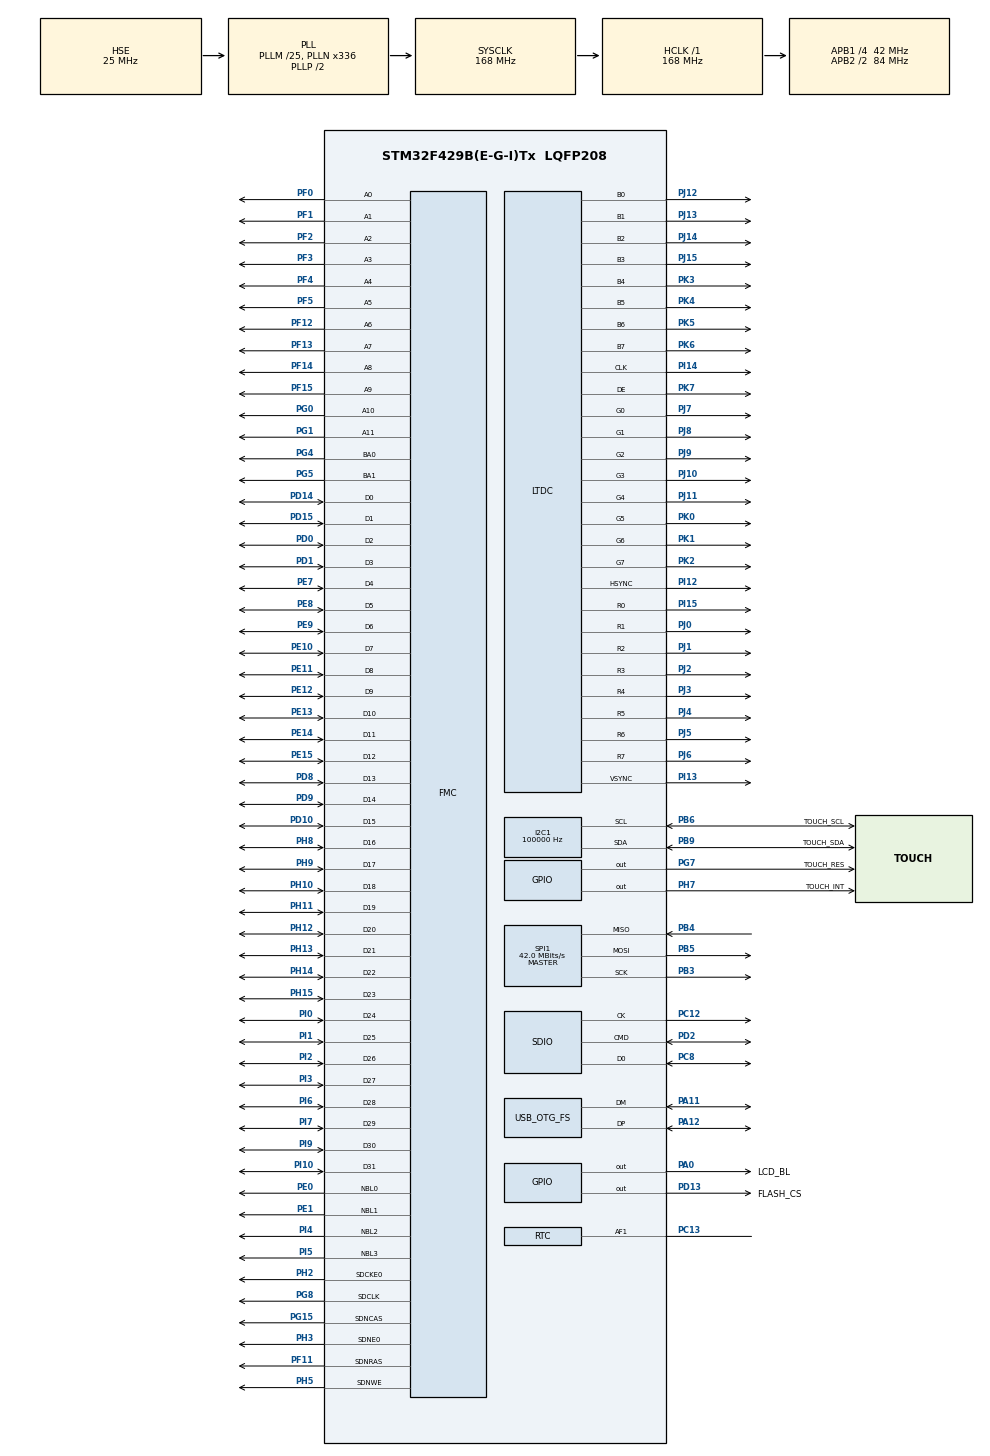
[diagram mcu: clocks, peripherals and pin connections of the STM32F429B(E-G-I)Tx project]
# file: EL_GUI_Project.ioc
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DMA2D.ColorMode=DMA2D_OUTPUT_RGB565
Dma.Request0=SPI1_RX
Dma.Request1=SPI1_TX
Dma.SPI1_RX.0.Direction=DMA_PERIPH_TO_MEMORY
Dma.SPI1_RX.0.FIFOMode=DMA_FIFOMODE_DISABLE
Dma.SPI1_RX.0.Instance=DMA2_Stream0
Dma.SPI1_RX.0.MemDataAlignment=DMA_MDATAALIGN_BYTE
Dma.SPI1_RX.0.MemInc=DMA_MINC_ENABLE
Dma.SPI1_RX.0.Mode=DMA_NORMAL
Dma.SPI1_RX.0.PeriphDataAlignment=DMA_PDATAALIGN_BYTE
Dma.SPI1_RX.0.PeriphInc=DMA_PINC_DISABLE
Dma.SPI1_RX.0.Priority=DMA_PRIORITY_LOW
Dma.SPI1_TX.1.Direction=DMA_MEMORY_TO_PERIPH
Dma.SPI1_TX.1.FIFOMode=DMA_FIFOMODE_DISABLE
Dma.SPI1_TX.1.Instance=DMA2_Stream3
Dma.SPI1_TX.1.MemDataAlignment=DMA_MDATAALIGN_BYTE
Dma.SPI1_TX.1.MemInc=DMA_MINC_DISABLE
Dma.SPI1_TX.1.Mode=DMA_NORMAL
Dma.SPI1_TX.1.PeriphDataAlignment=DMA_PDATAALIGN_BYTE
Dma.SPI1_TX.1.PeriphInc=DMA_PINC_DISABLE
Dma.SPI1_TX.1.Priority=DMA_PRIORITY_LOW
FMC.CASLatency1=FMC_SDRAM_CAS_LATENCY_3
FMC.ExitSelfRefreshDelay1=7
FMC.LoadToActiveDelay1=2
FMC.RCDDelay1=2
FMC.RPDelay1=2
FMC.ReadBurst1=FMC_SDRAM_RBURST_ENABLE
FMC.RowCycleDelay1=7
FMC.SDClockPeriod1=FMC_SDRAM_CLOCK_PERIOD_2
FMC.SelfRefreshTime1=4
FMC.WriteRecoveryTime1=3
FREERTOS.Tasks01=GUI_Task,24,8192,TouchGFX_Task_start,Default,NULL,Dynamic,NULL,NULL
FREERTOS.configENABLE_FPU=1
FREERTOS.configTOTAL_HEAP_SIZE=49152
FREERTOS.configUSE_NEWLIB_REENTRANT=1
I2C1.ClockSpeed=100000
LTDC.ActiveH=480
LTDC.ActiveW=800
LTDC.Alpha0_L0=0
LTDC.Alpha_L0=255
LTDC.Blue_L0=0
LTDC.DEPolarity=LTDC_DEPOLARITY_AL
LTDC.FBStartAdress_L0=0xC0000000
LTDC.FBStartAdress_L1=0xC0200000
LTDC.Green_L0=0
LTDC.HBP=46
LTDC.HFP=210
LTDC.HSPolarity=LTDC_HSPOLARITY_AH
LTDC.HSync=10
LTDC.ImageHeight_L0=480
LTDC.ImageHeight_L1=480
LTDC.ImageWidth_L0=800
LTDC.ImageWidth_L1=800
LTDC.Layers=0
LTDC.PCPolarity=LTDC_PCPOLARITY_IPC
LTDC.PixelFormat_L0=LTDC_PIXEL_FORMAT_RGB565
LTDC.Red_L0=0
LTDC.VBP=23
LTDC.VFP=22
LTDC.VSPolarity=LTDC_VSPOLARITY_AH
LTDC.VSync=10
LTDC.WindowX1_L0=800
LTDC.WindowX1_L1=800
LTDC.WindowY1_L0=480
LTDC.WindowY1_L1=480
Mcu.Family=STM32F4
Mcu.Name=STM32F429B(E-G-I)Tx
Mcu.Package=LQFP208
NVIC.DMA2_Stream0_IRQn=true\:5\:0\:false\:false\:true\:true\:true\:true\:true
NVIC.DMA2_Stream3_IRQn=true\:5\:0\:false\:false\:true\:true\:true\:true\:true
NVIC.FLASH_IRQn=true\:5\:0\:true\:false\:true\:true\:true\:true\:true
NVIC.FMC_IRQn=true\:5\:0\:true\:false\:true\:true\:true\:true\:true
NVIC.FPU_IRQn=true\:5\:0\:true\:false\:true\:true\:true\:false\:true
NVIC.LTDC_ER_IRQn=true\:5\:0\:true\:false\:true\:true\:true\:true\:true
NVIC.LTDC_IRQn=true\:5\:0\:true\:false\:true\:true\:true\:true\:true
NVIC.OTG_FS_IRQn=true\:5\:0\:false\:false\:true\:true\:false\:true\:true
NVIC.PriorityGroup=NVIC_PRIORITYGROUP_4
NVIC.RCC_IRQn=true\:5\:0\:true\:false\:true\:true\:true\:false\:true
NVIC.SDIO_IRQn=true\:5\:0\:false\:false\:true\:true\:true\:true\:true
NVIC.SPI1_IRQn=true\:5\:0\:false\:false\:true\:true\:true\:true\:true
NVIC.TIM8_TRG_COM_TIM14_IRQn=true\:4\:0\:true\:false\:true\:false\:false\:true\:true
NVIC.TimeBase=TIM8_TRG_COM_TIM14_IRQn
NVIC.TimeBaseIP=TIM14
PA0/WKUP.GPIO_Label=LCD_BL
PA0/WKUP.Signal=GPIO_Output
PA11.Mode=Device_Only
PA11.Signal=USB_OTG_FS_DM
PA12.Mode=Device_Only
PA12.Signal=USB_OTG_FS_DP
PA13.Mode=Serial_Wire
PA13.Signal=SYS_JTMS-SWDIO
PA14.Mode=Serial_Wire
PA14.Signal=SYS_JTCK-SWCLK
PB3.Mode=Full_Duplex_Master
PB3.Signal=SPI1_SCK
PB4.Mode=Full_Duplex_Master
PB4.Signal=SPI1_MISO
PB5.Mode=Full_Duplex_Master
PB5.Signal=SPI1_MOSI
PB6.GPIO_Label=TOUCH_SCL
PB6.GPIO_Pu=GPIO_NOPULL
PB6.GPIO_Speed=GPIO_SPEED_FREQ_VERY_HIGH
PB6.Mode=I2C
PB6.Signal=I2C1_SCL
PB9.GPIO_Label=TOUCH_SDA
PB9.GPIO_Pu=GPIO_NOPULL
PB9.Mode=I2C
PB9.Signal=I2C1_SDA
PC12.GPIO_PuPd=GPIO_PULLUP
PC12.Mode=SD_1_bit
PC12.Signal=SDIO_CK
PC13.Mode=Calibration_512Hz
PC13.Signal=RTC_AF1
PC14/OSC32_IN.Mode=LSE-External-Oscillator
PC14/OSC32_IN.Signal=RCC_OSC32_IN
PC15/OSC32_OUT.Mode=LSE-External-Oscillator
PC15/OSC32_OUT.Signal=RCC_OSC32_OUT
PC8.GPIO_PuPd=GPIO_PULLUP
PC8.Mode=SD_1_bit
PC8.Signal=SDIO_D0
PD0.Signal=FMC_D2_DA2
PD1.Signal=FMC_D3_DA3
PD10.Signal=FMC_D15_DA15
PD13.GPIO_Label=FLASH_CS
PD13.GPIO_Speed=GPIO_SPEED_FREQ_HIGH
PD13.PinState=GPIO_PIN_SET
PD13.Signal=GPIO_Output
PD14.Signal=FMC_D0_DA0
PD15.Signal=FMC_D1_DA1
PD2.GPIO_PuPd=GPIO_PULLUP
PD2.Mode=SD_1_bit
PD2.Signal=SDIO_CMD
PD8.Signal=FMC_D13_DA13
PD9.Signal=FMC_D14_DA14
PE0.Signal=FMC_NBL0
PE1.Signal=FMC_NBL1
PE10.Signal=FMC_D7_DA7
PE11.Signal=FMC_D8_DA8
PE12.Signal=FMC_D9_DA9
PE13.Signal=FMC_D10_DA10
PE14.Signal=FMC_D11_DA11
PE15.Signal=FMC_D12_DA12
PE7.Signal=FMC_D4_DA4
PE8.Signal=FMC_D5_DA5
PE9.Signal=FMC_D6_DA6
PF0.Signal=FMC_A0
PF1.Signal=FMC_A1
PF11.Signal=FMC_SDNRAS
PF12.Signal=FMC_A6
PF13.Signal=FMC_A7
PF14.Signal=FMC_A8
PF15.Signal=FMC_A9
PF2.Signal=FMC_A2
PF3.Signal=FMC_A3
PF4.Signal=FMC_A4
PF5.Signal=FMC_A5
PG0.Signal=FMC_A10
PG1.Signal=FMC_A11
PG15.Signal=FMC_SDNCAS
PG4.Signal=FMC_A14_BA0
PG5.Signal=FMC_A15_BA1
PG7.GPIO_Label=TOUCH_RES
PG7.PinState=GPIO_PIN_SET
PG7.Signal=GPIO_Output
PG8.Signal=FMC_SDCLK
PH0/OSC_IN.Mode=HSE-External-Oscillator
PH0/OSC_IN.Signal=RCC_OSC_IN
PH1/OSC_OUT.Mode=HSE-External-Oscillator
PH1/OSC_OUT.Signal=RCC_OSC_OUT
PH10.Signal=FMC_D18
PH11.Signal=FMC_D19
PH12.Signal=FMC_D20
PH13.Signal=FMC_D21
PH14.Signal=FMC_D22
PH15.Signal=FMC_D23
PH2.Mode=SdramChipSelect1_1
PH2.Signal=FMC_SDCKE0
PH3.Mode=SdramChipSelect1_1
PH3.Signal=FMC_SDNE0
PH5.Signal=FMC_SDNWE
PH7.GPIO_Label=TOUCH_INT
PH7.GPIO_Speed=GPIO_SPEED_FREQ_MEDIUM
PH7.PinState=GPIO_PIN_SET
PH7.Signal=GPIO_Output
PH8.Signal=FMC_D16
PH9.Signal=FMC_D17
PI0.Signal=FMC_D24
PI1.Signal=FMC_D25
PI10.Signal=FMC_D31
PI12.GPIO_PuPd=GPIO_NOPULL
PI12.GPIO_Speed=GPIO_SPEED_FREQ_VERY_HIGH
PI12.Mode=RGB888
PI12.Signal=LTDC_HSYNC
PI13.GPIO_PuPd=GPIO_NOPULL
PI13.GPIO_Speed=GPIO_SPEED_FREQ_VERY_HIGH
PI13.Mode=RGB888
PI13.Signal=LTDC_VSYNC
PI14.GPIO_PuPd=GPIO_NOPULL
PI14.GPIO_Speed=GPIO_SPEED_FREQ_VERY_HIGH
PI14.Mode=RGB888
PI14.Signal=LTDC_CLK
PI15.GPIO_PuPd=GPIO_NOPULL
PI15.GPIO_Speed=GPIO_SPEED_FREQ_VERY_HIGH
PI15.Mode=RGB888
PI15.Signal=LTDC_R0
PI2.Signal=FMC_D26
PI3.Signal=FMC_D27
PI4.Signal=FMC_NBL2
PI5.Signal=FMC_NBL3
PI6.Signal=FMC_D28
PI7.Signal=FMC_D29
PI9.Signal=FMC_D30
PJ0.GPIO_PuPd=GPIO_NOPULL
PJ0.GPIO_Speed=GPIO_SPEED_FREQ_VERY_HIGH
PJ0.Mode=RGB888
PJ0.Signal=LTDC_R1
PJ1.GPIO_PuPd=GPIO_NOPULL
PJ1.GPIO_Speed=GPIO_SPEED_FREQ_VERY_HIGH
PJ1.Mode=RGB888
PJ1.Signal=LTDC_R2
PJ10.GPIO_PuPd=GPIO_NOPULL
PJ10.GPIO_Speed=GPIO_SPEED_FREQ_VERY_HIGH
PJ10.Mode=RGB888
PJ10.Signal=LTDC_G3
PJ11.GPIO_PuPd=GPIO_NOPULL
PJ11.GPIO_Speed=GPIO_SPEED_FREQ_VERY_HIGH
PJ11.Mode=RGB888
PJ11.Signal=LTDC_G4
PJ12.GPIO_PuPd=GPIO_NOPULL
PJ12.GPIO_Speed=GPIO_SPEED_FREQ_VERY_HIGH
PJ12.Mode=RGB888
PJ12.Signal=LTDC_B0
PJ13.GPIO_PuPd=GPIO_NOPULL
PJ13.GPIO_Speed=GPIO_SPEED_FREQ_VERY_HIGH
PJ13.Mode=RGB888
PJ13.Signal=LTDC_B1
PJ14.GPIO_PuPd=GPIO_NOPULL
PJ14.GPIO_Speed=GPIO_SPEED_FREQ_VERY_HIGH
PJ14.Mode=RGB888
PJ14.Signal=LTDC_B2
PJ15.GPIO_PuPd=GPIO_NOPULL
PJ15.GPIO_Speed=GPIO_SPEED_FREQ_VERY_HIGH
PJ15.Mode=RGB888
PJ15.Signal=LTDC_B3
PJ2.GPIO_PuPd=GPIO_NOPULL
PJ2.GPIO_Speed=GPIO_SPEED_FREQ_VERY_HIGH
PJ2.Mode=RGB888
PJ2.Signal=LTDC_R3
PJ3.GPIO_PuPd=GPIO_NOPULL
PJ3.GPIO_Speed=GPIO_SPEED_FREQ_VERY_HIGH
PJ3.Mode=RGB888
PJ3.Signal=LTDC_R4
PJ4.GPIO_PuPd=GPIO_NOPULL
PJ4.GPIO_Speed=GPIO_SPEED_FREQ_VERY_HIGH
PJ4.Mode=RGB888
PJ4.Signal=LTDC_R5
PJ5.GPIO_PuPd=GPIO_NOPULL
PJ5.GPIO_Speed=GPIO_SPEED_FREQ_VERY_HIGH
PJ5.Mode=RGB888
PJ5.Signal=LTDC_R6
PJ6.GPIO_PuPd=GPIO_NOPULL
PJ6.GPIO_Speed=GPIO_SPEED_FREQ_VERY_HIGH
PJ6.Mode=RGB888
PJ6.Signal=LTDC_R7
PJ7.GPIO_PuPd=GPIO_NOPULL
PJ7.GPIO_Speed=GPIO_SPEED_FREQ_VERY_HIGH
PJ7.Mode=RGB888
PJ7.Signal=LTDC_G0
PJ8.GPIO_PuPd=GPIO_NOPULL
PJ8.GPIO_Speed=GPIO_SPEED_FREQ_VERY_HIGH
PJ8.Mode=RGB888
PJ8.Signal=LTDC_G1
PJ9.GPIO_PuPd=GPIO_NOPULL
PJ9.GPIO_Speed=GPIO_SPEED_FREQ_VERY_HIGH
PJ9.Mode=RGB888
PJ9.Signal=LTDC_G2
PK0.GPIO_PuPd=GPIO_NOPULL
PK0.GPIO_Speed=GPIO_SPEED_FREQ_VERY_HIGH
PK0.Mode=RGB888
PK0.Signal=LTDC_G5
PK1.GPIO_PuPd=GPIO_NOPULL
PK1.GPIO_Speed=GPIO_SPEED_FREQ_VERY_HIGH
PK1.Mode=RGB888
PK1.Signal=LTDC_G6
PK2.GPIO_PuPd=GPIO_NOPULL
PK2.GPIO_Speed=GPIO_SPEED_FREQ_VERY_HIGH
PK2.Mode=RGB888
PK2.Signal=LTDC_G7
PK3.GPIO_PuPd=GPIO_NOPULL
PK3.GPIO_Speed=GPIO_SPEED_FREQ_VERY_HIGH
PK3.Mode=RGB888
PK3.Signal=LTDC_B4
PK4.GPIO_PuPd=GPIO_NOPULL
PK4.GPIO_Speed=GPIO_SPEED_FREQ_VERY_HIGH
PK4.Mode=RGB888
PK4.Signal=LTDC_B5
PK5.GPIO_PuPd=GPIO_NOPULL
PK5.GPIO_Speed=GPIO_SPEED_FREQ_VERY_HIGH
PK5.Mode=RGB888
PK5.Signal=LTDC_B6
PK6.GPIO_PuPd=GPIO_NOPULL
PK6.GPIO_Speed=GPIO_SPEED_FREQ_VERY_HIGH
PK6.Mode=RGB888
PK6.Signal=LTDC_B7
PK7.GPIO_PuPd=GPIO_NOPULL
PK7.GPIO_Speed=GPIO_SPEED_FREQ_VERY_HIGH
PK7.Mode=RGB888
PK7.Signal=LTDC_DE
ProjectManager.HeapSize=0x800
ProjectManager.StackSize=0x1000
ProjectManager.TargetToolchain=STM32CubeIDE
RCC.48MHZClocksFreq_Value=48000000
RCC.AHBFreq_Value=168000000
RCC.APB1CLKDivider=RCC_HCLK_DIV4
RCC.APB1Freq_Value=42000000
RCC.APB1TimFreq_Value=84000000
RCC.APB2CLKDivider=RCC_HCLK_DIV2
RCC.APB2Freq_Value=84000000
RCC.APB2TimFreq_Value=168000000
RCC.CortexFreq_Value=168000000
RCC.DATA_CACHE_ENABLE=1
RCC.HCLKFreq_Value=168000000
RCC.HSE_VALUE=25000000
RCC.HSI_VALUE=16000000
RCC.INSTRUCTION_CACHE_ENABLE=1
RCC.PLLM=25
RCC.PLLN=336
RCC.PLLQ=7
RCC.PLLSAIN=136
RCC.PREFETCH_ENABLE=1
RCC.RCC_RTC_Clock_Source=RCC_RTCCLKSOURCE_LSE
RCC.RCC_RTC_Clock_SourceVirtual=RCC_RTCCLKSOURCE_LSE
RCC.SYSCLKFreq_VALUE=168000000
RCC.SYSCLKSource=RCC_SYSCLKSOURCE_PLLCLK
RCC.VCOOutputFreq_Value=336000000
SDIO.ClockDiv=8
SH.FMC_A0.0=FMC_A0,12b-sda1
SH.FMC_A1.0=FMC_A1,12b-sda1
SH.FMC_A10.0=FMC_A10,12b-sda1
SH.FMC_A11.0=FMC_A11,12b-sda1
SH.FMC_A14_BA0.0=FMC_BA0,FourSdramBanks1
SH.FMC_A15_BA1.0=FMC_BA1,FourSdramBanks1
SH.FMC_A2.0=FMC_A2,12b-sda1
SH.FMC_A3.0=FMC_A3,12b-sda1
SH.FMC_A4.0=FMC_A4,12b-sda1
SH.FMC_A5.0=FMC_A5,12b-sda1
SH.FMC_A6.0=FMC_A6,12b-sda1
SH.FMC_A7.0=FMC_A7,12b-sda1
SH.FMC_A8.0=FMC_A8,12b-sda1
SH.FMC_A9.0=FMC_A9,12b-sda1
SH.FMC_D0_DA0.0=FMC_D0,sd-32b-d1
SH.FMC_D10_DA10.0=FMC_D10,sd-32b-d1
SH.FMC_D11_DA11.0=FMC_D11,sd-32b-d1
SH.FMC_D12_DA12.0=FMC_D12,sd-32b-d1
SH.FMC_D13_DA13.0=FMC_D13,sd-32b-d1
SH.FMC_D14_DA14.0=FMC_D14,sd-32b-d1
SH.FMC_D15_DA15.0=FMC_D15,sd-32b-d1
SH.FMC_D16.0=FMC_D16,sd-32b-d1
SH.FMC_D17.0=FMC_D17,sd-32b-d1
SH.FMC_D18.0=FMC_D18,sd-32b-d1
SH.FMC_D19.0=FMC_D19,sd-32b-d1
SH.FMC_D1_DA1.0=FMC_D1,sd-32b-d1
SH.FMC_D20.0=FMC_D20,sd-32b-d1
SH.FMC_D21.0=FMC_D21,sd-32b-d1
SH.FMC_D22.0=FMC_D22,sd-32b-d1
SH.FMC_D23.0=FMC_D23,sd-32b-d1
SH.FMC_D24.0=FMC_D24,sd-32b-d1
SH.FMC_D25.0=FMC_D25,sd-32b-d1
SH.FMC_D26.0=FMC_D26,sd-32b-d1
SH.FMC_D27.0=FMC_D27,sd-32b-d1
SH.FMC_D28.0=FMC_D28,sd-32b-d1
SH.FMC_D29.0=FMC_D29,sd-32b-d1
SH.FMC_D2_DA2.0=FMC_D2,sd-32b-d1
SH.FMC_D30.0=FMC_D30,sd-32b-d1
SH.FMC_D31.0=FMC_D31,sd-32b-d1
SH.FMC_D3_DA3.0=FMC_D3,sd-32b-d1
SH.FMC_D4_DA4.0=FMC_D4,sd-32b-d1
SH.FMC_D5_DA5.0=FMC_D5,sd-32b-d1
SH.FMC_D6_DA6.0=FMC_D6,sd-32b-d1
SH.FMC_D7_DA7.0=FMC_D7,sd-32b-d1
SH.FMC_D8_DA8.0=FMC_D8,sd-32b-d1
SH.FMC_D9_DA9.0=FMC_D9,sd-32b-d1
SH.FMC_NBL0.0=FMC_NBL0,Sd4ByteEnable1
SH.FMC_NBL1.0=FMC_NBL1,Sd4ByteEnable1
SH.FMC_NBL2.0=FMC_NBL2,Sd4ByteEnable1
SH.FMC_NBL3.0=FMC_NBL3,Sd4ByteEnable1
SH.FMC_SDCLK.0=FMC_SDCLK,12b-sda1
SH.FMC_SDNCAS.0=FMC_SDNCAS,12b-sda1
SH.FMC_SDNRAS.0=FMC_SDNRAS,12b-sda1
SH.FMC_SDNWE.0=FMC_SDNWE,12b-sda1
SPI1.CLKPhase=SPI_PHASE_2EDGE
SPI1.CLKPolarity=SPI_POLARITY_HIGH
SPI1.CalculateBaudRate=42.0 MBits/s
SPI1.Direction=SPI_DIRECTION_2LINES
SPI1.Mode=SPI_MODE_MASTER
SPI1.VirtualType=VM_MASTER
STMicroelectronics.X-CUBE-TOUCHGFX.4.23.1.ApplicationCcGraphicsJjApplication=TouchGFXOoGenerator
STMicroelectronics.X-CUBE-TOUCHGFX.4.23.1.tgfx_address1=0xC0000000
STMicroelectronics.X-CUBE-TOUCHGFX.4.23.1.tgfx_address2=0xC0100000
STMicroelectronics.X-CUBE-TOUCHGFX.4.23.1.tgfx_buffering_strategy=Double
STMicroelectronics.X-CUBE-TOUCHGFX.4.23.1.tgfx_datareader_block_size=3200
STMicroelectronics.X-CUBE-TOUCHGFX.4.23.1.tgfx_display_interface=disp_ltdc
STMicroelectronics.X-CUBE-TOUCHGFX.4.23.1.tgfx_hardware_accelerator=dma_2d
STMicroelectronics.X-CUBE-TOUCHGFX.4.23.1.tgfx_location=By Address
STMicroelectronics.X-CUBE-TOUCHGFX.4.23.1.tgfx_oswrapper=CMSIS V2
STMicroelectronics.X-CUBE-TOUCHGFX.4.23.1.tgfx_vector_rendering=Disabled
STMicroelectronics.X-CUBE-TOUCHGFX.4.23.1.tgfx_vsync=vsync_ltdc
STMicroelectronics.X-CUBE-TOUCHGFX.4.23.1_IsPackSelfContextualization=true
USB_DEVICE.CLASS_NAME_FS=MSC
USB_DEVICE.VirtualMode-MSC_FS=Msc
USB_DEVICE.VirtualModeFS=Msc_FS
USB_OTG_FS.VirtualMode=Device_Only
VP_CRC_VS_CRC.Mode=CRC_Activate
VP_DMA2D_VS_DMA2D.Mode=DMA2D_Activate
VP_FREERTOS_VS_CMSIS_V2.Mode=CMSIS_V2
VP_RTC_VS_RTC_Activate.Mode=RTC_Enabled
VP_RTC_VS_RTC_Calendar.Mode=RTC_Calendar
VP_STMicroelectronics.X-CUBE-TOUCHGFX_VS_GraphicsJjApplication_4.23.1.Mode=GraphicsJjApplication
VP_SYS_VS_tim14.Mode=TIM14
VP_USB_DEVICE_VS_USB_DEVICE_MSC_FS.Mode=MSC_FS
board=custom

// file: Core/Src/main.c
/* USER CODE BEGIN Header */
/**
  ******************************************************************************
  * @file           : main.c
  * @brief          : Main program body
  ******************************************************************************
  * @attention
  *
  * <h2><center>&copy; Copyright (c) 2021 STMicroelectronics.
  * All rights reserved.</center></h2>
  *
  * This software component is licensed by ST under Ultimate Liberty license
  * SLA0044, the "License"; You may not use this file except in compliance with
  * the License. You may obtain a copy of the License at:
  *                             www.st.com/SLA0044
  *
  ******************************************************************************
  */
/* USER CODE END Header */
#include "main.h"
#include "cmsis_os.h"
#include "app_touchgfx.h"
#include "usb_device.h"

/* USER CODE BEGIN Includes */
#include "mt48lc4m32b2.h"

/* USER CODE END Includes */

CRC_HandleTypeDef hcrc;

DMA2D_HandleTypeDef hdma2d;

I2C_HandleTypeDef hi2c1;

LTDC_HandleTypeDef hltdc;

RTC_HandleTypeDef hrtc;

SD_HandleTypeDef hsd;

SPI_HandleTypeDef hspi1;
DMA_HandleTypeDef hdma_spi1_rx;
DMA_HandleTypeDef hdma_spi1_tx;

SDRAM_HandleTypeDef hsdram1;

/* Definitions for GUI_Task */
osThreadId_t GUI_TaskHandle;
const osThreadAttr_t GUI_Task_attributes = {
  .name = "GUI_Task",
  .stack_size = 8192 * 4,
  .priority = (osPriority_t) osPriorityNormal,
};
/* USER CODE BEGIN PV */
uint8_t ucHeap[ configTOTAL_HEAP_SIZE ] __attribute__((section(".ccmram")));
// configAPPLICATION_ALLOCATED_HEAP=1

/* USER CODE END PV */

void SystemClock_Config(void);
static void MX_GPIO_Init(void);
static void MX_DMA_Init(void);
static void MX_LTDC_Init(void);
static void MX_RTC_Init(void);
static void MX_CRC_Init(void);
static void MX_I2C1_Init(void);
static void MX_SDIO_SD_Init(void);
static void MX_FMC_Init(void);
static void MX_SPI1_Init(void);
static void MX_DMA2D_Init(void);
void TouchGFX_Task_start(void *argument);

/* USER CODE BEGIN PFP */
HAL_SD_CardInfoTypeDef SDCardInfo;
/* USER CODE END PFP */

int main(void)
{

  /* MCU Configuration--------------------------------------------------------*/

  /* Reset of all peripherals, Initializes the Flash interface and the Systick. */
  HAL_Init();

  /* Configure the system clock */
  SystemClock_Config();

  /* Initialize all configured peripherals */
  MX_GPIO_Init();
  MX_DMA_Init();
//  MX_LTDC_Init();
  MX_RTC_Init();
  MX_CRC_Init();
  MX_I2C1_Init();
  MX_SDIO_SD_Init();
  MX_FMC_Init();
  MX_SPI1_Init();
// MX_DMA2D_Init();
  MX_TouchGFX_Init();
  /* Call PreOsInit function */
  MX_TouchGFX_PreOSInit();
  /* USER CODE BEGIN 2 */

  //HAL_GPIO_WritePin(LCD_BL_GPIO_Port, LCD_BL_Pin, GPIO_PIN_SET);

 // DataReader_HPMode_Init();
  /* USER CODE END 2 */

  /* Init scheduler */
  osKernelInitialize();

  /* Create the thread(s) */
  /* creation of GUI_Task */
  GUI_TaskHandle = osThreadNew(TouchGFX_Task_start, NULL, &GUI_Task_attributes);

  /* Start scheduler */
  osKernelStart();

  /* We should never get here as control is now taken by the scheduler */
  /* Infinite loop */
  while (1)
  {

  }
}

void SystemClock_Config(void)
{
  RCC_OscInitTypeDef RCC_OscInitStruct = {0};
  RCC_ClkInitTypeDef RCC_ClkInitStruct = {0};

  /** Configure the main internal regulator output voltage
  */
  __HAL_RCC_PWR_CLK_ENABLE();
  __HAL_PWR_VOLTAGESCALING_CONFIG(PWR_REGULATOR_VOLTAGE_SCALE1);

  /** Initializes the RCC Oscillators according to the specified parameters
  * in the RCC_OscInitTypeDef structure.
  */
  RCC_OscInitStruct.OscillatorType = RCC_OSCILLATORTYPE_HSE|RCC_OSCILLATORTYPE_LSE;
  RCC_OscInitStruct.HSEState = RCC_HSE_ON;
  RCC_OscInitStruct.LSEState = RCC_LSE_ON;
  RCC_OscInitStruct.PLL.PLLState = RCC_PLL_ON;
  RCC_OscInitStruct.PLL.PLLSource = RCC_PLLSOURCE_HSE;
  RCC_OscInitStruct.PLL.PLLM = 25;
  RCC_OscInitStruct.PLL.PLLN = 336;
  RCC_OscInitStruct.PLL.PLLP = RCC_PLLP_DIV2;
  RCC_OscInitStruct.PLL.PLLQ = 7;
  if (HAL_RCC_OscConfig(&RCC_OscInitStruct) != HAL_OK)
  {
    Error_Handler();
  }

  /** Initializes the CPU, AHB and APB buses clocks
  */
  RCC_ClkInitStruct.ClockType = RCC_CLOCKTYPE_HCLK|RCC_CLOCKTYPE_SYSCLK
                              |RCC_CLOCKTYPE_PCLK1|RCC_CLOCKTYPE_PCLK2;
  RCC_ClkInitStruct.SYSCLKSource = RCC_SYSCLKSOURCE_PLLCLK;
  RCC_ClkInitStruct.AHBCLKDivider = RCC_SYSCLK_DIV1;
  RCC_ClkInitStruct.APB1CLKDivider = RCC_HCLK_DIV4;
  RCC_ClkInitStruct.APB2CLKDivider = RCC_HCLK_DIV2;

  if (HAL_RCC_ClockConfig(&RCC_ClkInitStruct, FLASH_LATENCY_5) != HAL_OK)
  {
    Error_Handler();
  }
}

static void MX_CRC_Init(void)
{

  hcrc.Instance = CRC;
  if (HAL_CRC_Init(&hcrc) != HAL_OK)
  {
    Error_Handler();
  }

}

static void MX_DMA2D_Init(void)
{

  hdma2d.Instance = DMA2D;
  hdma2d.Init.Mode = DMA2D_M2M;
  hdma2d.Init.ColorMode = DMA2D_OUTPUT_RGB565;
  hdma2d.Init.OutputOffset = 0;
  hdma2d.LayerCfg[1].InputOffset = 0;
  hdma2d.LayerCfg[1].InputColorMode = DMA2D_INPUT_RGB565;
  hdma2d.LayerCfg[1].AlphaMode = DMA2D_NO_MODIF_ALPHA;
  hdma2d.LayerCfg[1].InputAlpha = 0;
  if (HAL_DMA2D_Init(&hdma2d) != HAL_OK)
  {
    Error_Handler();
  }
  if (HAL_DMA2D_ConfigLayer(&hdma2d, 1) != HAL_OK)
  {
    Error_Handler();
  }

}

static void MX_I2C1_Init(void)
{

  hi2c1.Instance = I2C1;
  hi2c1.Init.ClockSpeed = 100000;
  hi2c1.Init.DutyCycle = I2C_DUTYCYCLE_2;
  hi2c1.Init.OwnAddress1 = 0;
  hi2c1.Init.AddressingMode = I2C_ADDRESSINGMODE_7BIT;
  hi2c1.Init.DualAddressMode = I2C_DUALADDRESS_DISABLE;
  hi2c1.Init.OwnAddress2 = 0;
  hi2c1.Init.GeneralCallMode = I2C_GENERALCALL_DISABLE;
  hi2c1.Init.NoStretchMode = I2C_NOSTRETCH_DISABLE;
  if (HAL_I2C_Init(&hi2c1) != HAL_OK)
  {
    Error_Handler();
  }

  /** Configure Analogue filter
  */
  if (HAL_I2CEx_ConfigAnalogFilter(&hi2c1, I2C_ANALOGFILTER_ENABLE) != HAL_OK)
  {
    Error_Handler();
  }

  /** Configure Digital filter
  */
  if (HAL_I2CEx_ConfigDigitalFilter(&hi2c1, 0) != HAL_OK)
  {
    Error_Handler();
  }

}

static void MX_LTDC_Init(void)
{

  LTDC_LayerCfgTypeDef pLayerCfg = {0};

  hltdc.Instance = LTDC;
  hltdc.Init.HSPolarity = LTDC_HSPOLARITY_AH;
  hltdc.Init.VSPolarity = LTDC_VSPOLARITY_AH;
  hltdc.Init.DEPolarity = LTDC_DEPOLARITY_AL;
  hltdc.Init.PCPolarity = LTDC_PCPOLARITY_IPC;
  hltdc.Init.HorizontalSync = 9;
  hltdc.Init.VerticalSync = 9;
  hltdc.Init.AccumulatedHBP = 55;
  hltdc.Init.AccumulatedVBP = 32;
  hltdc.Init.AccumulatedActiveW = 855;
  hltdc.Init.AccumulatedActiveH = 512;
  hltdc.Init.TotalWidth = 1065;
  hltdc.Init.TotalHeigh = 534;
  hltdc.Init.Backcolor.Blue = 0;
  hltdc.Init.Backcolor.Green = 0;
  hltdc.Init.Backcolor.Red = 0;
  if (HAL_LTDC_Init(&hltdc) != HAL_OK)
  {
    Error_Handler();
  }
  pLayerCfg.WindowX0 = 0;
  pLayerCfg.WindowX1 = 800;
  pLayerCfg.WindowY0 = 0;
  pLayerCfg.WindowY1 = 480;
  pLayerCfg.PixelFormat = LTDC_PIXEL_FORMAT_RGB565;
  pLayerCfg.Alpha = 255;
  pLayerCfg.Alpha0 = 0;
  pLayerCfg.BlendingFactor1 = LTDC_BLENDING_FACTOR1_CA;
  pLayerCfg.BlendingFactor2 = LTDC_BLENDING_FACTOR2_CA;
  pLayerCfg.FBStartAdress = 0xC0000000;
  pLayerCfg.ImageWidth = 800;
  pLayerCfg.ImageHeight = 480;
  pLayerCfg.Backcolor.Blue = 0;
  pLayerCfg.Backcolor.Green = 0;
  pLayerCfg.Backcolor.Red = 0;
  if (HAL_LTDC_ConfigLayer(&hltdc, &pLayerCfg, 0) != HAL_OK)
  {
    Error_Handler();
  }

}

static void MX_RTC_Init(void)
{

  RTC_TimeTypeDef sTime = {0};
  RTC_DateTypeDef sDate = {0};

  /** Initialize RTC Only
  */
  hrtc.Instance = RTC;
  hrtc.Init.HourFormat = RTC_HOURFORMAT_24;
  hrtc.Init.AsynchPrediv = 127;
  hrtc.Init.SynchPrediv = 255;
  hrtc.Init.OutPut = RTC_OUTPUT_DISABLE;
  hrtc.Init.OutPutPolarity = RTC_OUTPUT_POLARITY_HIGH;
  hrtc.Init.OutPutType = RTC_OUTPUT_TYPE_OPENDRAIN;
  if (HAL_RTC_Init(&hrtc) != HAL_OK)
  {
    Error_Handler();
  }

  /** Initialize RTC and set the Time and Date
  */
  sTime.Hours = 0x0;
  sTime.Minutes = 0x0;
  sTime.Seconds = 0x0;
  sTime.DayLightSaving = RTC_DAYLIGHTSAVING_NONE;
  sTime.StoreOperation = RTC_STOREOPERATION_RESET;
  if (HAL_RTC_SetTime(&hrtc, &sTime, RTC_FORMAT_BCD) != HAL_OK)
  {
    Error_Handler();
  }
  sDate.WeekDay = RTC_WEEKDAY_MONDAY;
  sDate.Month = RTC_MONTH_JANUARY;
  sDate.Date = 0x1;
  sDate.Year = 0x0;

  if (HAL_RTC_SetDate(&hrtc, &sDate, RTC_FORMAT_BCD) != HAL_OK)
  {
    Error_Handler();
  }

  /** Enable Calibrartion
  */
  if (HAL_RTCEx_SetCalibrationOutPut(&hrtc, RTC_CALIBOUTPUT_512HZ) != HAL_OK)
  {
    Error_Handler();
  }
  /* USER CODE BEGIN RTC_Init 2 */
  HAL_RTCEx_EnableBypassShadow(&hrtc);
  /* USER CODE END RTC_Init 2 */

}

static void MX_SDIO_SD_Init(void)
{

  hsd.Instance = SDIO;
  hsd.Init.ClockEdge = SDIO_CLOCK_EDGE_RISING;
  hsd.Init.ClockBypass = SDIO_CLOCK_BYPASS_DISABLE;
  hsd.Init.ClockPowerSave = SDIO_CLOCK_POWER_SAVE_DISABLE;
  hsd.Init.BusWide = SDIO_BUS_WIDE_1B;
  hsd.Init.HardwareFlowControl = SDIO_HARDWARE_FLOW_CONTROL_DISABLE;
  hsd.Init.ClockDiv = 8;
  if (HAL_SD_Init(&hsd) != HAL_OK)
  {
    Error_Handler();
  }

}

static void MX_SPI1_Init(void)
{

  /* SPI1 parameter configuration*/
  hspi1.Instance = SPI1;
  hspi1.Init.Mode = SPI_MODE_MASTER;
  hspi1.Init.Direction = SPI_DIRECTION_2LINES;
  hspi1.Init.DataSize = SPI_DATASIZE_8BIT;
  hspi1.Init.CLKPolarity = SPI_POLARITY_HIGH;
  hspi1.Init.CLKPhase = SPI_PHASE_2EDGE;
  hspi1.Init.NSS = SPI_NSS_SOFT;
  hspi1.Init.BaudRatePrescaler = SPI_BAUDRATEPRESCALER_2;
  hspi1.Init.FirstBit = SPI_FIRSTBIT_MSB;
  hspi1.Init.TIMode = SPI_TIMODE_DISABLE;
  hspi1.Init.CRCCalculation = SPI_CRCCALCULATION_DISABLE;
  hspi1.Init.CRCPolynomial = 10;
  if (HAL_SPI_Init(&hspi1) != HAL_OK)
  {
    Error_Handler();
  }

}

static void MX_DMA_Init(void)
{

  /* DMA controller clock enable */
  __HAL_RCC_DMA2_CLK_ENABLE();

  /* DMA interrupt init */
  /* DMA2_Stream0_IRQn interrupt configuration */
  HAL_NVIC_SetPriority(DMA2_Stream0_IRQn, 5, 0);
  HAL_NVIC_EnableIRQ(DMA2_Stream0_IRQn);
  /* DMA2_Stream3_IRQn interrupt configuration */
  HAL_NVIC_SetPriority(DMA2_Stream3_IRQn, 5, 0);
  HAL_NVIC_EnableIRQ(DMA2_Stream3_IRQn);

}

/* FMC initialization function */
static void MX_FMC_Init(void)
{

  FMC_SDRAM_TimingTypeDef SdramTiming = {0};

  /** Perform the SDRAM1 memory initialization sequence
  */
  hsdram1.Instance = FMC_SDRAM_DEVICE;
  /* hsdram1.Init */
  hsdram1.Init.SDBank = FMC_SDRAM_BANK1;
  hsdram1.Init.ColumnBitsNumber = FMC_SDRAM_COLUMN_BITS_NUM_8;
  hsdram1.Init.RowBitsNumber = FMC_SDRAM_ROW_BITS_NUM_12;
  hsdram1.Init.MemoryDataWidth = FMC_SDRAM_MEM_BUS_WIDTH_32;
  hsdram1.Init.InternalBankNumber = FMC_SDRAM_INTERN_BANKS_NUM_4;
  hsdram1.Init.CASLatency = FMC_SDRAM_CAS_LATENCY_3;
  hsdram1.Init.WriteProtection = FMC_SDRAM_WRITE_PROTECTION_DISABLE;
  hsdram1.Init.SDClockPeriod = FMC_SDRAM_CLOCK_PERIOD_2;
  hsdram1.Init.ReadBurst = FMC_SDRAM_RBURST_ENABLE;
  hsdram1.Init.ReadPipeDelay = FMC_SDRAM_RPIPE_DELAY_0;
  /* SdramTiming */
  SdramTiming.LoadToActiveDelay = 2;
  SdramTiming.ExitSelfRefreshDelay = 7;
  SdramTiming.SelfRefreshTime = 4;
  SdramTiming.RowCycleDelay = 7;
  SdramTiming.WriteRecoveryTime = 3;
  SdramTiming.RPDelay = 2;
  SdramTiming.RCDDelay = 2;

  if (HAL_SDRAM_Init(&hsdram1, &SdramTiming) != HAL_OK)
  {
    Error_Handler( );
  }

  /* USER CODE BEGIN FMC_Init 2 */
  static MT48LC4M32B2_Context_t pRegMode;

  pRegMode.BurstLength = MT48LC4M32B2_BURST_LENGTH_8;
  pRegMode.BurstType = MT48LC4M32B2_BURST_TYPE_SEQUENTIAL;
  pRegMode.CASLatency = MT48LC4M32B2_CAS_LATENCY_3;
  pRegMode.OperationMode = MT48LC4M32B2_OPERATING_MODE_STANDARD;
  pRegMode.RefreshMode = MT48LC4M32B2_AUTOREFRESH_MODE_CMD ;
  pRegMode.RefreshRate = REFRESH_COUNT;
  pRegMode.WriteBurstMode =MT48LC4M32B2_WRITEBURST_MODE_SINGLE;
  pRegMode.TargetBank = FMC_SDRAM_CMD_TARGET_BANK1;

  if(MT48LC4M32B2_Init(&hsdram1, &pRegMode) != MT48LC4M32B2_OK)
	  while(1)
	  {
		  HAL_Delay(10);
	  }
  /* USER CODE END FMC_Init 2 */
}

static void MX_GPIO_Init(void)
{
  GPIO_InitTypeDef GPIO_InitStruct = {0};

  /* GPIO Ports Clock Enable */
  __HAL_RCC_GPIOC_CLK_ENABLE();
  __HAL_RCC_GPIOI_CLK_ENABLE();
  __HAL_RCC_GPIOF_CLK_ENABLE();
  __HAL_RCC_GPIOH_CLK_ENABLE();
  __HAL_RCC_GPIOA_CLK_ENABLE();
  __HAL_RCC_GPIOJ_CLK_ENABLE();
  __HAL_RCC_GPIOG_CLK_ENABLE();
  __HAL_RCC_GPIOE_CLK_ENABLE();
  __HAL_RCC_GPIOD_CLK_ENABLE();
  __HAL_RCC_GPIOK_CLK_ENABLE();
  __HAL_RCC_GPIOB_CLK_ENABLE();

  /*Configure GPIO pin Output Level */
  HAL_GPIO_WritePin(LCD_BL_GPIO_Port, LCD_BL_Pin, GPIO_PIN_RESET);

  /*Configure GPIO pin Output Level */
  HAL_GPIO_WritePin(TOUCH_INT_GPIO_Port, TOUCH_INT_Pin, GPIO_PIN_SET);

  /*Configure GPIO pin Output Level */
  HAL_GPIO_WritePin(FLASH_CS_GPIO_Port, FLASH_CS_Pin, GPIO_PIN_SET);

  /*Configure GPIO pin Output Level */
  HAL_GPIO_WritePin(TOUCH_RES_GPIO_Port, TOUCH_RES_Pin, GPIO_PIN_SET);

  /*Configure GPIO pin : LCD_BL_Pin */
  GPIO_InitStruct.Pin = LCD_BL_Pin;
  GPIO_InitStruct.Mode = GPIO_MODE_OUTPUT_PP;
  GPIO_InitStruct.Pull = GPIO_NOPULL;
  GPIO_InitStruct.Speed = GPIO_SPEED_FREQ_LOW;
  HAL_GPIO_Init(LCD_BL_GPIO_Port, &GPIO_InitStruct);

  /*Configure GPIO pin : TOUCH_INT_Pin */
  GPIO_InitStruct.Pin = TOUCH_INT_Pin;
  GPIO_InitStruct.Mode = GPIO_MODE_OUTPUT_PP;
  GPIO_InitStruct.Pull = GPIO_NOPULL;
  GPIO_InitStruct.Speed = GPIO_SPEED_FREQ_MEDIUM;
  HAL_GPIO_Init(TOUCH_INT_GPIO_Port, &GPIO_InitStruct);

  /*Configure GPIO pin : FLASH_CS_Pin */
  GPIO_InitStruct.Pin = FLASH_CS_Pin;
  GPIO_InitStruct.Mode = GPIO_MODE_OUTPUT_PP;
  GPIO_InitStruct.Pull = GPIO_NOPULL;
  GPIO_InitStruct.Speed = GPIO_SPEED_FREQ_HIGH;
  HAL_GPIO_Init(FLASH_CS_GPIO_Port, &GPIO_InitStruct);

  /*Configure GPIO pin : TOUCH_RES_Pin */
  GPIO_InitStruct.Pin = TOUCH_RES_Pin;
  GPIO_InitStruct.Mode = GPIO_MODE_OUTPUT_PP;
  GPIO_InitStruct.Pull = GPIO_NOPULL;
  GPIO_InitStruct.Speed = GPIO_SPEED_FREQ_LOW;
  HAL_GPIO_Init(TOUCH_RES_GPIO_Port, &GPIO_InitStruct);

}

/* USER CODE BEGIN 4 */
void LCD_BL_Ctrl(uint8_t bl)
{
	if(bl)
		HAL_GPIO_WritePin(LCD_BL_GPIO_Port, LCD_BL_Pin, GPIO_PIN_SET);
	else
		HAL_GPIO_WritePin(LCD_BL_GPIO_Port, LCD_BL_Pin, GPIO_PIN_RESET);
}
/* USER CODE END 4 */

void TouchGFX_Task_start(void *argument)
{
  /* init code for USB_DEVICE */
  MX_USB_DEVICE_Init();
  /* USER CODE BEGIN 5 */
  CopyFlashToSdram(0xD00000);
  MX_LTDC_Init();
  MX_DMA2D_Init();
  LCD_BL_Ctrl(1);
  //GT9147_Init();
  TouchGFX_Task(argument);
  /* Infinite loop */
  for(;;)
  {
    osDelay(1);
  }
  /* USER CODE END 5 */
}

void HAL_TIM_PeriodElapsedCallback(TIM_HandleTypeDef *htim)
{
  if (htim->Instance == TIM14) {
    HAL_IncTick();
  }
}

void Error_Handler(void)
{
  __disable_irq();
  while (1)
  {
  }
}
